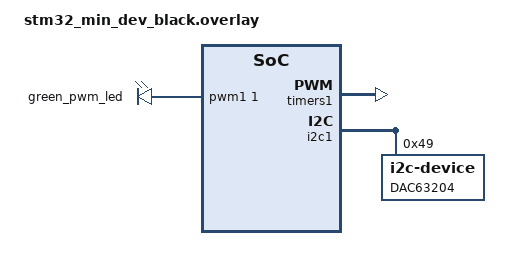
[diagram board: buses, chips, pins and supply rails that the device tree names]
/ {
    pwmleds: pwmleds {
        compatible = "pwm-leds";
        status = "okay";

        green_pwm_led: green_pwm_led {
            pwms = <&pwm1 1 PWM_MSEC(20) PWM_POLARITY_NORMAL>;
        };
    };

    aliases {
        led0 = &led;
        pwm-led0 = &green_pwm_led;
        uart0 = &usart1;
    };

};

&timers1 {
    status = "okay";
    st,prescaler = <10000>;

    pwm1: pwm {
        status = "okay";
        pinctrl-0 = <&tim1_ch1_pwm_out_pe9>;
        pinctrl-names = "default";
    };
};

// Need to define the AF2 for timer1
&pinctrl {
    /omit-if-no-ref/ tim1_ch1_pwm_out_pe9: tim1_ch1_pwm_out_pe9 {
        pinmux = <STM32F1_PINMUX('E', 9, ALTERNATE, TIM1_REMAP2)>;
    };
};

// USART over DMA
&usart1 {
    dmas = <&dma1 4 (STM32_DMA_PERIPH_TX | STM32_DMA_PRIORITY_HIGH)>,
           <&dma1 5 (STM32_DMA_PERIPH_RX | STM32_DMA_PRIORITY_HIGH)>;
    dma-names = "tx", "rx";
};

&dma1 {
    status = "okay";
};

/*
 * I2C configuration
 * I2C1: scl_pb6 sda_pb7
 */
&i2c1 {
    dac63204: dac63204@49 {
        compatible = "i2c-device";
        reg = <0x49>;
        label = "DAC63204";
    };
};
